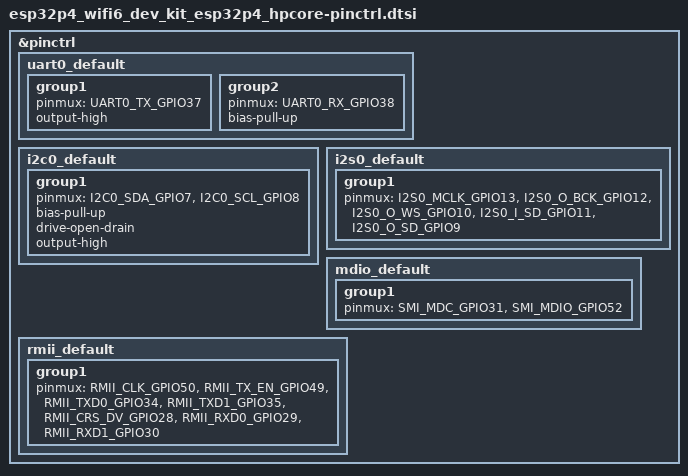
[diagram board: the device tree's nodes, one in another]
/*
 * Copyright (c) 2026 Process Mission
 *
 * SPDX-License-Identifier: Apache-2.0
 */

#include <zephyr/dt-bindings/pinctrl/esp-pinctrl-common.h>
#include <zephyr/dt-bindings/pinctrl/esp32p4-pinctrl.h>
#include <zephyr/dt-bindings/pinctrl/esp32p4-gpio-sigmap.h>

&pinctrl {
	uart0_default: uart0_default {
		group1 {
			pinmux = <UART0_TX_GPIO37>;
			output-high;
		};

		group2 {
			pinmux = <UART0_RX_GPIO38>;
			bias-pull-up;
		};
	};

	i2c0_default: i2c0_default {
		group1 {
			pinmux = <I2C0_SDA_GPIO7>,
				 <I2C0_SCL_GPIO8>;
			bias-pull-up;
			drive-open-drain;
			output-high;
		};
	};

	i2s0_default: i2s0_default {
		group1 {
			pinmux = <I2S0_MCLK_GPIO13>,
				 <I2S0_O_BCK_GPIO12>,
				 <I2S0_O_WS_GPIO10>,
				 <I2S0_I_SD_GPIO11>,
				 <I2S0_O_SD_GPIO9>;
		};
	};

	mdio_default: mdio_default {
		group1 {
			pinmux = <SMI_MDC_GPIO31>,
				 <SMI_MDIO_GPIO52>;
		};
	};

	rmii_default: rmii_default {
		group1 {
			pinmux = <RMII_CLK_GPIO50>,
				 <RMII_TX_EN_GPIO49>,
				 <RMII_TXD0_GPIO34>,
				 <RMII_TXD1_GPIO35>,
				 <RMII_CRS_DV_GPIO28>,
				 <RMII_RXD0_GPIO29>,
				 <RMII_RXD1_GPIO30>;
		};
	};
};
